# dm648_cslr_spi register map
Vendor: Texas Instruments
Peripheral module from a debugger description file.
Registers are 32-bit, access not given, reset 0x0 unless marked. A register's access mark holds for its fields unless they carry their own. Offsets are as the file gives them; lines under a group give offsets from that group; [hi:lo] are bit positions; {n}, {i} and the like mark numbered series; 'fields as' and 'values as' point back to an identical list; <NAME> marks a mode.

## SPI — Serial Peripheral Interface
0x00 SPIGCR0 — SPI Global Control Register 0
  [0] RESET rw — This bit needs to be set before any operation on SPI can be done 0: SPI is in reset state 1: SPI is out of reset state
    0=IN_RESET; 1=OUT_OF_RESET
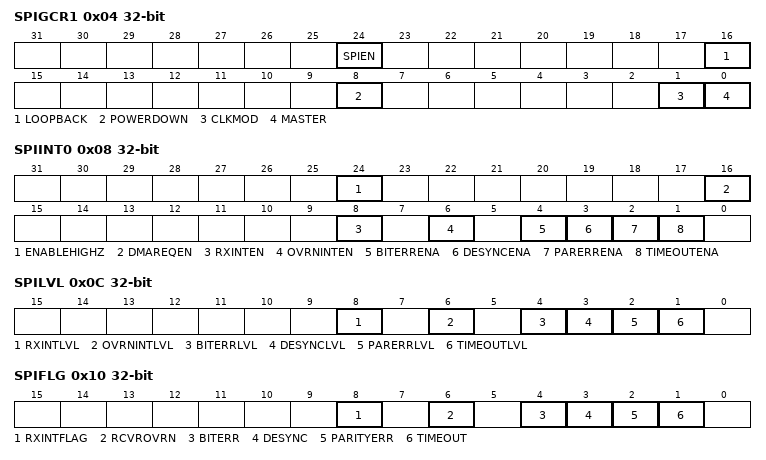
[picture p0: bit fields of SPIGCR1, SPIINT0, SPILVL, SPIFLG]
0x04 SPIGCR1 — SPI Global Control Register 1
  [24] SPIEN rw — SPI enable Holds the SPI in a reset state after a chip reset. The SPI is enabled only after a 1 is written to this bit. This bit must be setto 1 after all other SPI configuration bits have been written. This prevents an invalid operation of the SPI while the clock polarity is being changed. When this bit is 0, the SPI shift registers (SPIDAT0 and SPIDAT1) is held in reset mode and forced to 0x0000 The RXINTFLAG (SPIFLG.8) and RCVROVRN (SPIFLG.6) bits are also held in reset mode and forced to 0 when this bit is 0. SPICLK is disabled when this bit is 0 0: SPI is in reset 1: Activates SPI
    0=DISABLED; 1=ENABLED
  [16] LOOPBACK rw — Internal loop-back test mode The internal self-test option can be enabled by setting this bit. If the SPISIMO and SPISOMI pins are configured with SPI functionality, then the SPISIMOpin is internally connected to the SPISOMI pin. The transmit data is looped back as receive data and is stored in the receive field of the concerned buffer.Externally, during loop-back operation, the SPICLK pin outputs an inactive value and SPISOMI remains in high-impedance state. The SPI has to be initialized in master mode before the loop-back can be selected. If the SPI is initialized in slave mode or a data transfer is ongoing, errors may result
    0=DISABLE; 1=ENABLE
  [8] POWERDOWN rw — When active, the SPI state machines enter a powerdown state 0: SPI in active mode 1: SPI in powerdown mode
    0=ACTIVE; 1=POWERDOWN
  [1] CLKMOD rw — Selects either an internal or external clock source. This bit also determines the I/O direction of the SPIENA and SPISCS[3:0] pins in functional mode 0: Clock is external 1: Clock is internal
    0=EXTERNAL; 1=INTERNAL
  [0] MASTER rw — SPISIMO/SPISOMI pin direction determination Determines the direction of the SPISIMO and SPISOMI pins 0: SPISIMO pin an input, SPISOMI pin an output 1: SPISOMI pin an input, SPISIMO pin an output
    0=SPISIMO_OUTPUT_SPISOMI_OUTPUT; 1=SPISOMI_INPUT_SPISIMO_OUTPUT
0x08 SPIINT0 — SPI Interrupt Register
  [24] ENABLEHIGHZ rw — SPIENA pin high-z enable When active, the pin (when it is configured as a WAIT functional output signal in a slave SPI) is forced to place it's output in high-z when not driving a low signal. If inactive, then the pin will output both a high and a low signal 0: SPIENA pin is a value 1: SPIENA pin is in high-z
    0=SPIENA_VALUE; 1=SPIENA_HIZ
  [16] DMAREQEN rw — DMA request enable Enables the DMA request signal to be generated for both receive and transmit channels 0: DMA is not used 1: DMA is used
    0=DISABLED; 1=ENABLED
  [8] RXINTEN rw — An interrupt is to be generated when the RXINTFLAG bit (SPICTRL3.0) is set by hardware. Otherwise, no interrupt will be generated 0: Interrupt will not be generated 1: Interrupt will be generated
    0=DISABLED; 1=ENABLED
  [6] OVRNINTEN rw — Overrun interrupt enable An interrupt is to be generated when the RCVR OVRN flag bit (SPIFLG.6) is set by hardware. Otherwise, no interrupt will be generated 0: Overrun interrupt will not be generated 1: Overrun interrupt will be generated
    0=DISABLED; 1=ENABLED
  [4] BITERRENA rw — Enables interrupt on bit error 0: No interrupt asserted upon bit error 1: Enables an interrupt on a bit error (BITERR = 1)
    0=DISABLED; 1=ENABLED
  [3] DESYNCENA rw — Enables interrupt on de-synchronized slave DESYNCENA is used in master mode only 0: No interrupt asserted upon de-synchronization error 1: Enables an interrupt on de-synchronization of the slave (DESYNC = 1)
    0=DISABLED; 1=ENABLED
  [2] PARERRENA rw — Enables interrupt on parity error 0: No interrupt asserted upon parity error 1: Enables an interrupt on a parity error (PARITYERR = 1)
    0=DISABLED; 1=ENABLED
  [1] TIMEOUTENA rw — Enables interrupt on ENA signal time-out 0: No interrupt asserted upon ENA signal time-out 1: Enables an interrupt on a time-out of the ENA signal (TIMEOUT = 1)
    0=DISABLED; 1=ENABLED
0x0C SPILVL — SPI Level Register
  [8] RXINTLVL rw — Receive interrupt level 0: Receive interrupt is mapped to interrupt line INT0 1: Receive interrupt is mapped to interrupt line INT1
    0=RCV_INT0; 1=RCV_INT1
  [6] OVRNINTLVL rw — Receive Overrun interrupt level 0: Receive Overrun interrupt is mapped to interrupt line INT0 1: Receive Overrun interrupt is mapped to interrupt line INT1
    0=RCV_INT0; 1=RCV_INT1
  [4] BITERRLVL rw — Bit error interrupt level 0: Bit error interrupt is mapped to interrupt line INT0 1: Bit error interrupt is mapped to interrupt line INT1
    0=INT0; 1=INT1
  [3] DESYNCLVL rw — De-synchronized slave interrupt level DESYNCLVL is used in master mode only 0: An interrupt due to de-synchronization of the slave (DESYNC = 1) is mapped to interrupt line INT0 1: An interrupt due to de-synchronization of the slave (DESYNC = 1) is mapped to interrupt line INT1
    0=INT0; 1=INT1
  [2] PARERRLVL rw — Parity error interrupt level 0: A parity error interrupt (PARITYERR = 1) is mapped to interrupt line INT0 1: A parity error interrupt (PARITYERR = 1) is mapped to interrupt line INT1
    0=INT0; 1=INT1
  [1] TIMEOUTLVL rw — ENA signal time-out interrupt level 0: An interrupt on a time-out of the ENA signal (TIMEOUT = 1) is mapped to interrupt line INT0 1: An interrupt on a time-out of the ENA signal (TIMEOUT = 1) is mapped to interrupt line INT1
    0=INT0; 1=INT1
0x10 SPIFLG — SPI Flag Register
  [8] RXINTFLAG — Serves as the interrupt flag This flag is set when a word is received and copied into the buffer register (SPIBUF). If RXINTEN is enabled, an interrupt is also generated. During emulation mode, however, a read to the emulation register (SPIEMU) does not clear this flag bit. This bit is cleared in one of four ways a) Reading the SPIBUF register b)Writing a 1 to this bit c) Writing a 0 to SPIEN (SPIGCR1.24) d) System reset 0: Interrupt condition did not occur 1: Interrupt condition did occur (access RC)
    0=ENABLED; 1=DISABLED
  [6] RCVROVRN — Receiver overrun flag This bit is a read/clear only flag. The SPI hardware sets this bit when an operation completes before the previous character has been read from the buffer. The bit indicates that the last received character has been overwritten and therefore lost. The SPI will generate an interrupt request if this bit is set and the OVRN INTEN bit (SPIINT0.6) is set high This bit is cleared in one of four ways: a) Reading the SPIBUF register b) Writing a 1 to this bit c) Writing a 0 to SPIEN (SPIGCR1.24) d) System reset 0: Overrun condition did not occur 1: Overrun condition has occurred (access RC)
    0=ENABLED; 1=DISABLED
  [4] BITERR — Mismatch of internal transmit data and transmitted data This flag is read/clear only flag, i.e. reading the flag will automatically clear it 0: No bit error occurred 1: A bit error occurred. The SPI samples the signal of the transmit pin (master: SIMO, slave: SOMI) at the receive point (half clock cycle after transmit point). If the sampled value differs from the transmitted value a bit error is detected and the Flag BITERR is set. If BIT-ERRENA is set an interrupt is asserted. A possible reason for a bit error can be a to high bit rate / capacitive load or another master/slave trying to transmit at the same time (access RC)
    0=NO_ERROR; 1=ERROR
  [3] DESYNC — De-synchronization of slave device This flag is read/clear only flag, i.e. reading the flag will automatically clear it De-synchronization monitor is active in master mode only 0: No slave de-synchronization detected 1: A slave device is de-synchronized. The master monitors the ENABLE signal coming from the slave device and sets the DESYNC flag if ENA is deactivated before the last reception point or after the last bit is transmitted plus tT2EDELAY. If DESYNCENA is set an interrupt is asserted. De-synchronization can occur if a slave device misses a clock edge coming from the master or is detecting an additional clock edge due to perturbation (access RC)
    0=ENABLED; 1=DISABLED
  [2] PARITYERR — Calculated parity differs from received parity bit This flag is read/clear only flag, i.e. reading the flag will automatically clear it 0: No parity error detected 1: A parity error occurred. If the parity generator is enabled (can be selected individually for each buffer) an even or odd parity bit is added at the end of a data word. During reception of the data word the parity generator calculates the reference parity and compares it to the received parity bit. In the event of a mismatch the PARITYERR flag is set and an interrupt is asserted if PARERRENA is set (access RC)
    0=NO_ERROR; 1=ERROR
  [1] TIMEOUT — Time-out due to non-activation of ENA signal This flag is read/clear only flag, i.e. reading the flag will automatically clear it 0: No ENA-signal time-out occurred 1: An ENA signal time-out occurred. The SPI generates a time-out because the slave hasn't responded in time by activating the ENA signal after the chip select signal has been activated. If a time-out condition is detected the corresponding chip select is deactivated immediately and the TIMEOUT flag is set. In addition the TIMOUT flag in the status field of the corresponding buffer is set. The transmit request of the concerned buffer is cleared, i.e. the SPIdoesn't restart a data transfer from this buffer (access RC)
    0=DISABLED; 1=ENABLED
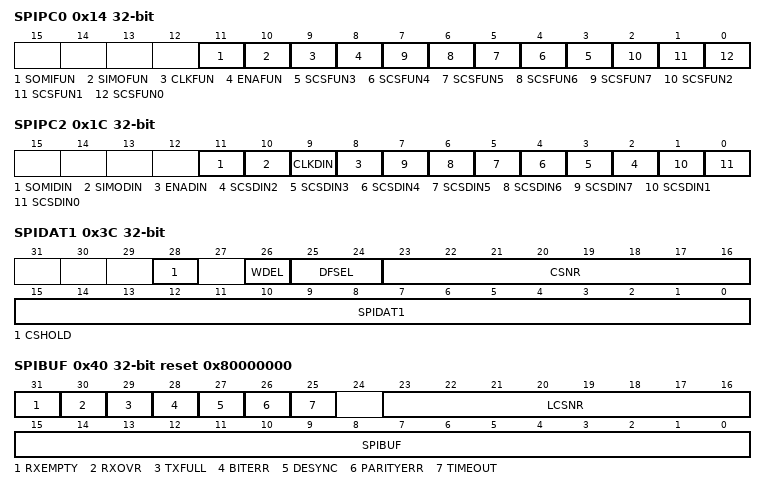
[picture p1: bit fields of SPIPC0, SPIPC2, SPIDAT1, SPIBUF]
0x14 SPIPC0 — SPI Pin Control Register 0
  [all] fields
    0=GPIO; 0=SPI
  [11] SOMIFUN rw — Slave out, master in function Determines whether the SPISOMI pin is to be used as a general-purpose I/O pin or as a SPI functional pin. 0: SPISOMI pin is a GPIO 1: SPISOMI pin is a SPI functional pin
  [10] SIMOFUN rw — Slave in, master out function Determines whether the SPISIMO pin is to be used as a general-purpose I/O pin, or as a SPI functional pin. 0: SPISIMO pin is a GPIO 1: SPISIMO pin is a SPI functional pin
  [9] CLKFUN rw — SPI clock function Determines whether the SPICLK pin is to be used as a general-purpose I/O pin, or as a SPI functional pin. 0: SPICLK pin is a GPIO 1: SPICLK pin is a SPI functional pin
  [8] ENAFUN rw — SPIENA function Determines whether the SPIENA pin is to be used as a general-purpose I/O pin, or as a SPI functional pin 0: SPIENA pin is a GPIO 1: SPIENA pin is a SPI functional pin
  [n] SCSFUN{n} rw (n=3..7) — SPISCS{n} function Determines whether the SPISCS{n} pin are to be used as a general-purpose I/O pin or as SPI functional pin. If the slave SPISCS{n} pin are in functional mode and receive an inactive high signal, the slave SPI will place it's output in high-z and disable shifting 0: SPISCS{n} pin is a GPIO 1: SPISCS{n} pin is a SPI functional pin
  [2] SCSFUN2 rw — SPISCS7 function Determines whether the SPISCS2 pin are to be used as a general-purpose I/O pin or as SPI functional pin. If the slave SPISCS2 pin are in functional mode and receive an inactive high signal, the slave SPI will place it's output in high-z and disable shifting 0: SPISCS2 pin is a GPIO 1: SPISCS2 pin is a SPI functional pin
  [1] SCSFUN1 rw — SPISCS1 function Determines whether the SPISCS1 pin are to be used as a general-purpose I/O pin or as SPI functional pin. If the slave SPISCS1 pin are in functional mode and receive an inactive high signal, the slave SPI will place it's output in high-z and disable shifting 0: SPISCS1 pin is a GPIO 1: SPISCS1 pin is a SPI functional pin
  [0] SCSFUN0 rw — SPISCS0 function Determines whether the SPISCS0 pin are to be used as a general-purpose I/O pin or as SPI functional pin. If the slave SPISCS0 pin are in functional mode and receive an inactive high signal, the slave SPI will place it's output in high-z and disable shifting 0: SPISCS0 pin is a GPIO 1: SPISCS0 pin is a SPI functional pin
0x1C SPIPC2 — SPI Pin Control Register 2
  [all] fields
    0=LOW; 1=HIGH
  [11] SOMIDIN ro — SPISOMI data in Reflects the value of the SPISOMI pin 0: Current value on SPISOMI pin is logic 0 1: Current value on SPISOMI pin is logic 1
  [10] SIMODIN ro — SPISIMO data in Reflects the value of the SPISIMO pin 0: Current value on SPISIMO pin is logic 0 1: Current value on SPISIMO pin is logic 1
  [9] CLKDIN ro — Clock data in Reflects the value of the SPICLK pin 0: Current value on SPICLK pin is logic 0 1: Current value on SPICLK pin is logic 1
  [8] ENADIN ro — SPIENA data in Reflects the value of the SPIENA pin 0: Current value on SPIENA pin is logic 0 1: Current value on SPIENA pin is logic 1
  [n] SCSDIN{n} ro (n=2..7) — SPISCS{n} data in Reflects the value of the SPISCS{n} pins 0: Current value on SPISCS{n} pin is logic 0 1: Current value on SPISCS{n} pin is logic 1
  [1] SCSDIN1 ro — SPISCS1data in Reflects the value of the SPISCS1 pins. 0: Current value on SPISCS1 pin is logic 0 1: Current value on SPISCS2 pin is logic 1
  [0] SCSDIN0 ro — SPISCS0data in Reflects the value of the SPISCS0 pins 0: Current value on SPISCS0 pin is logic 0 1: Current value on SPISCS0 pin is logic 1
0x3C SPIDAT1 — SPI Shift Register 1
  [28] CSHOLD rw — Chip select hold mode CSHOLD is considered in master mode only. In slave mode this bit has no meaning. CSHOLD defines the behavior of the chip select line at the end of a data transfer 0: The chip select signal is deactivated at the end of a transfer after the T2CDELAY time has passed. If two consecutive transfers are dedicated to the same chip select this chip select signal will be shortly deactivated before it is activated again 1: The chip select signal is held active at the end of a transfer until a control field with new data and control information is loaded into SPIDAT1. If the new chip select information equals the previous one the active chip select signal is extended until the end of transfer with CSHOLD cleared or until the chip select information changes
    0=DISABLED; 1=ENABLED
  [26] WDEL rw — Enable the delay counter at the end of the current transaction 0: No delay is inserted 1: After the transaction WDELAY of the corresponding data format is loaded into the delay counter. No transaction is performed until the counter is reset
    0=NODELAY; 1=DEYAL
  [25:24] DFSEL rw — Data word format select -------------------------------------------------------------------------------- DFSEL1 DFSEL0 Description --------------------------------------------------------------------------------- 0 0 Data word format 0 is selected 0 1 Data word format 1 is selected 1 0 Data word format 2 is selected 1 1 Data word format 3 is selected
  [23:16] CSNR rw — Chip select number CSNR defines the chip select that shall be activated during the data transfer
  [15:0] SPIDAT1 rw — SPI shift data 1 These bits make up the SPI shift register 1. Data is shifted out of the MSB (bit 15) and into the LSB (bit 0) SPIEN must be set to 1 before this register can be written to. Writing a 0 to the SPIEN register forces the lower 16 bits of the SPIDAT1 register to 0x00 Write to this register ONLY when using the automatic Slave Chip Select feature. A write to this register will drive the SPISCS signal low When data is read from this register, the value is indeterminate because of the shift operation. The value in the buffer register (SPIBUF) should be read after the shift operation is complete to determine what data was shifted into the SPIDAT1 register
0x40 SPIBUF reset 0x80000000 — SPI Buffer Register
  [31] RXEMPTY ro — Receive data buffer empty This flag is a read-only flag. When host reads the SPIBUF field or the whole SPIBUF register this will automatically set the RXEMPTY flag. When a data transfer has been finished and the received data is copied into SPIBUF the RXEMPTY flag is cleared 0: Data is received and copied into SPIBUF field 1: No data received since last reading of SPIBUF register
    0=YES; 1=NO
  [30] RXOVR — Receive data buffer overrun This flag is read/clear only flag, i.e. reading the flag will automatically clear it. When a data transfer has been finished and the received data is copied into the SPIBUF while RXEMPTY flag is already cleared RXOVR is set 0: No receive data overrun condition occurred since last time reading the status field 1: A receive data overrun condition occurred since last time reading the status field (access RC)
    0=NO; 1=YES
  [29] TXFULL ro — Transmit data buffer full This flag is a read-only flag. Writing into SPIDAT0 or SPIDAT1 field will automatically set the TXFULL flag. After transfer of the transmit data the TXFULL flag is cleared 0: No new transmit data from host since previous transfer of transmit data 1: Host provided new transmit data to SPIDAT0 or SPIDAT1
    0=NO; 1=YES
  [28] BITERR — Mismatch of internal transmit data and transmitted data This flag is read/clear only flag, i.e. reading the flag will automatically clear it. It represents a copy of the BITERR flag in SPIFLG 0: No bit error occurred 1: A bit error occurred. The SPI samples the signal of the transmit pin (master: SIMO, slave: SOMI) at the receive point (half clock cycle after transmit point). If the sampled value differs from the transmitted value a bit error is detected and the flag BITERR is set. A possible reason for a bit error can be noise, a to high bit rate / capacitive load or another master/slave trying to transmit at the same time (access RC)
    0=NO; 1=YES
  [27] DESYNC — De-synchronization of slave device This flag is read/clear only flag, i.e. reading the flag will automatically clear it. De-synchronization monitor is active in master mode only. DESYNC represents a copy of the DESYNC flag in SPIFLG 0: No slave de-synchronization detected 1: A slave device is de-synchronized. The master monitors the ENA signal coming from the slave device and sets the DESYNC flag if ENA is deactivated before the last reception point or after the last bit is transmitted plus t T2EDELAY. If DESYNCENA is set an interrupt is asserted. De-synchronization can occur if a slave device misses a clock edge coming from the master or is detecting an additional clock edge due to perturbation (access RC)
    0=NO; 1=YES
  [26] PARITYERR — Calculated parity differs from received parity bit This flag is read/clear only flag, i.e. reading the flag will automatically clear it. It represents a copy of the PARITYERR flag in SPIFLG 0: No parity error detected 1: A parity error occurred. If the parity generator is enabled (can be selected individually for each buffer) an even or odd parity bit is added at the end of a data word. During reception of the data word the parity generator calculates the reference parity and compares it to the received parity bit. In the event of a mismatch the PARITYERR flag is set (access RC)
    0=NO; 1=YES
  [25] TIMEOUT — Time-out due to non-activation of ENA signal This flag is read/clear only flag, i.e. reading the flag will automatically clear it 0: No ENA-signal time-out occurred 1: An ENA signal time-out occurred. The SPI generates a time-out because the slave hasn't responded in time by activating the ENA signal after the chip select signal has been activated. If a time-out condition is detected the corresponding chip select is deactivated immediately and the TIMEOUT flag is set. In addition the TIMOUT flag in the status field of the corresponding buffer and in the SPISTAT register is set (access RC)
    0=NO; 1=YES
  [23:16] LCSNR ro — LCSNR in the status field is a copy of CSNR in the corresponding control field It defines the chip select that has been activated during the last data transfer from the corresponding buffer. LCSNR is copied from the Kernel of SPI after transmission during write back of received data
  [15:0] SPIBUF ro — SPI Buffer The data in this register is the data transferred from the shift-register (SPIDAT). Since the data is shifted into the SPI most significant bit first, for word lengths less than 16, the data is stored right-justified in the register
0x44 SPIEMU — SPI Emulation Register
  [15:0] SPIEMU ro — SPI Emulation SPI emulation is a mirror of the SPIBUF register. The only difference between SPIEMU and SPIBUF is that a read from SPIEMU does not clear the RCVR OVRN (SPIFLG.6) or RXINTFLAG (SPIFLG.8) bits
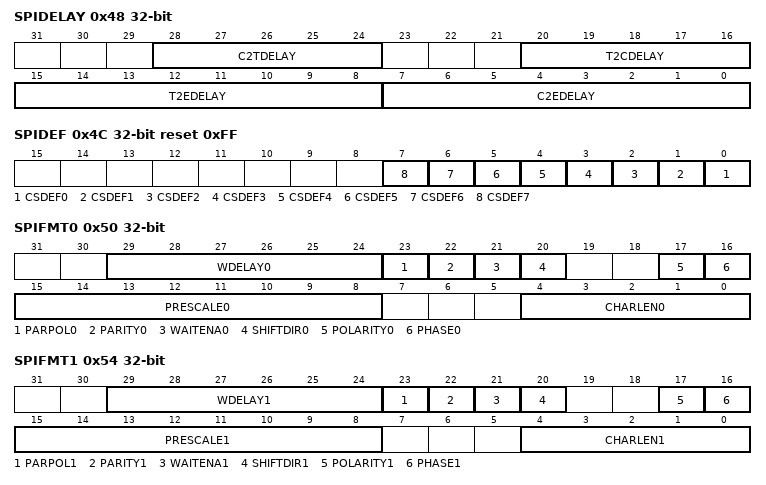
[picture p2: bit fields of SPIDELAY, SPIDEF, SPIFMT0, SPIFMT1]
0x48 SPIDELAY
  [28:24] C2TDELAY rw — Chip select active to transmit start delay C2TDELAY is used in master mode only. If the slave device indicates the ready-to-transfer status via the ENA signal, C2TDELAY time is not delayed after the ENA signal is activated. It defines a setup time for the slave device that delays the data transmission from the chip select active edge by a multiple of VBUSPCLK cycles. C2TDELAY can be configured between 2 and 33 VBUSPCLK cycles
  [20:16] T2CDELAY rw — Transmit end to chip select inactive delay T2CDELAY is used in master mode only. It defines a hold time for the slave device that delays the chip select deactivation by a multiple of VBUSPCLK cycles after the last bit is transferred. T2CDELAY can be configured between 1 and 32 VBUSPCLK cycles
  [15:8] T2EDELAY rw — Transmit data finished to ENA pin inactive timeout T2EDELAY is used in master mode only. It defines a time-out value as a multiple of SPI clock before the ENAble signal has to become inactive and after the CS becomes inactive. The SPI clock depends on which data format is selected. If the slave device is missing one or more clock edges, it's becoming de-synchronized. Although the master has finished the data transfer the slave is still waiting for the missed clock pulses and the ENA signal isn't disabled. The T2EDELAY defines a time-out value that triggers the DESYNC flag, if the ENA signal isn't deactivated in time
  [7:0] C2EDELAY rw — Chip select active to ENA signal active timeout C2EDELAY is utilized only in master mode and it applies only if the addressed slave generates an ENA signal as a hardware handshake response. C2EDELAY defines the maximum time between the SPI activates the chip select signal and the addressed slave has to respond by activating the ENA signal. C2EDELAY defines a time-out value as a multiple of SPI clocks. The SPI clock depends on whether data format 0 or data format 1 is selected. If the slave device is not responding with the ENA signal before the time-out value is reached, the TIMEOUT flag in SPISTAT register is set and a interrupt is asserted if enabled
0x4C SPIDEF reset 0xFF — SPI Chipselect Default Regsiter
  [all] fields
    0=CS_0; 1=CS_1
  [n] CSDEF{n} rw (n=0..7) — Chip select default pattern Master mode behavior. The CSDEF{n} register is output to the chip select pin when no transmission are currently performed. It allows the user to set a chip select pattern which deselect all the SPI slaves 0: If CSDEF{n} is set to "0" the corresponding chip select is set to "0" when no transfer occurs 1: If CSDEF{n} is set to "1" the corresponding chip select is set to "1" when no transfer occurs
0x50 SPIFMT0 — SPI Format 0 Register
  [29:24] WDELAY0 rw — Delay in between transmissions for data format 0 Idle time that will be applied at the end of the current transmission if the bit WDEL is set in the current buffer The delay to be applied is equal to: WDELAY * PVBUSPCLK + 2 * PVBUSPCLK
  [23] PARPOL0 rw — Parity polarity: even or odd. PARPOL0 can be modified in privilege mode only 0: If PARPOL0 is set to "0" and PARITY0 is enabled, a even parity flag is added at the end of the transmit data stream 1: If PARPOL0 is set to "1" and PARITY0 is enabled, a odd parity flag is added at the end of the transmit data stream
    0=EVEN; 1=ODD
  [22] PARITY0 rw — Parity enable for data format 0 0: No parity generation/ verification is performed for this data format 1: A parity is added after transfer of the data bit. At the end of a transfer the parity generator compares the received parity bit with the locally calculated parity flag. If the parity bits do not match the RXERR flag is set in the corresponding control field. The parity type (even or odd) can be selected via the PARPOL bit
    0=NOPARITY; 1=PARITY
  [21] WAITENA0 rw — Master waits for ENA signal from slave for data format 0. WAITENA is considered in master mode only. In slave mode this bit has no meaning. WAITENA enables a flexible SPI network where slaves with ENA signal and slaves without ENA signal can be mixed. WAITENA defines for each buffer whether the addressed slave generates the ENA signal or does not 0: The SPI does not wait for the ENA signal from the slaves and directly starts the transfer 1: Before the SPI starts the data transfer it waits for the ENA signal to become low. If the ENA signal is not pulled down by the addressed slave before the internal time-out counter (CE2DELAY) expires
    0=NO_WAIT; 1=WAIT
  [20] SHIFTDIR0 rw — Shift direction for data format 0 With bit SHIFTDIR0 the shift direction for data format 0 can be selected 0: Data format 0 shift direction: Most significant bit is shifted out first 1: Data format 0 shift direction: Least significant bit is shifted out first
    0=MSB; 1=LSB
  [17] POLARITY0 rw — SPI data format 0 clock polarity POLARITY0 defines the clock polarity of data format 0. POLARITY0 can be modified in privilege mode only 0: If POLARITY0 is set to "0" the SPI clock signal is low-inactive, i.e. before and after data transfer the clock signal is low 1: If POLARITY0 is set to "1" the SPI clock signal is high-inactive, i.e. before and after data transfer the clock signal is high
    0=LOW; 1=HIGH
  [16] PHASE0 rw — SPI Data format 0 clock delay PHASE0 defines the clock delay of data format 0. PHASE0 can be modified in privilege mode only 0: If PHASE0 is set to "0" the SPI clock signal is not delayed versus the transmit / receive data stream. The first data bit is transmitted with the first clock edge and the first bit is received with the second (inverse) clock edge 1: If PHASE0 is set to "1" the SPI clock signal is delayed by a half SPI clock cycle versus the transmit / receive data stream. The first transmit bit has to output prior to the first clock edge. Master and slave receive the first bit with the first edge
    0=NO_DELAY; 1=DELAY
  [15:8] PRESCALE0 rw — SPI data format 0 prescaler PRESCALE0 can be modified in privilege mode only PRESCALE0 determines the bit transfer rate of data format 0 if the SPI is the network master. PRESCALE0 is directly derived from VBUSPCLK. If the SPI is configured as slave, PRESCALE0 DOES NOT NEED to be configured. When PRESCALE0 is set to zero (0), the SPI clock rate is VBUSPCLK/2
  [4:0] CHARLEN0 rw — SPI data format 0 data word length CHARLEN0 defines the word length of data format 0. Legal values are 0x02 (data word length = 2 bit) to 0x10 (data word length = 16). Illegal values, such as 0x00 or 0x1F are not detected and their effect is indeterminate
0x54 SPIFMT1 — SPI Format 1 Register
  [29:24] WDELAY1 rw — Delay in between transmissions for data format 1 Idle time that will be applied at the end of the current transmission if the bit WDEL is set in the current buffer The delay to be applied is equal to: WDELAY * PVBUSPCLK + 2 * PVBUSPCLK
  [23] PARPOL1 rw — Parity polarity: even or odd. PARPOL1 can be modified in privilege mode only 0: If PARPOL1 is set to "0" and PARITY1 is enabled, a even parity flag is added at the end of the transmit data stream 1: If PARPOL1 is set to "1" and PARITY1 is enabled, a odd parity flag is added at the end of the transmit data stream
    0=EVEN; 1=ODD
  [22] PARITY1 rw — Parity enable for data format 1 0: No parity generation/ verification is performed for this data format 1: A parity is added after transfer of the data bit. At the end of a transfer the parity generator compares the received parity bit with the locally calculated parity flag. If the parity bits do not match the RXERR flag is set in the corresponding control field. The parity type (even or odd) can be selected via the PARPOL bit
    0=NOPARITY; 1=PARITY
  [21] WAITENA1 rw — Master waits for ENA signal from slave for data format1 WAITENA is considered in master mode only. In slave mode this bit has no meaning. WAITENA enables a flexible SPI network where slaves with ENA signal and slaves without ENA signal can be mixed. WAITENA defines for each buffer whether the addressed slave generates the ENA signal or does not 0: The SPI does not wait for the ENA signal from the slaves and directly starts the transfer 1: Before the SPI starts the data transfer it waits for the ENA signal to become low. If the ENA signal is not pulled down by the addressed slave before the internal time-out counter (CE2DELAY) expires
    0=NO_WAIT; 1=WAIT
  [20] SHIFTDIR1 rw — Shift direction for data format 1 With bit SHIFTDIR1 the shift direction for data format 1 can be selected 0: Data format 1shift direction: Most significant bit is shifted out first 1: Data format 1shift direction: Least significant bit is shifted out first
    0=MSB; 1=LSB
  [17] POLARITY1 rw — SPI data format 1 clock polarity POLARITY1 defines the clock polarity of data format 1. POLARITY1 can be modified in privilege mode only 0: If POLARITY1 is set to "0" the SPI clock signal is low-inactive, i.e. before and after data transfer the clock signal is low 1: If POLARITY1 is set to "1" the SPI clock signal is high-inactive, i.e. before and after data transfer the clock signal is high
    0=LOW; 1=HIGH
  [16] PHASE1 rw — SPI Data format 1 clock delay PHASE1 defines the clock delay of data format 1. PHASE1 can be modified in privilege mode only 0: If PHASE1 is set to "0" the SPI clock signal is not delayed versus the transmit / receive data stream. The first data bit is transmitted with the first clock edge and the first bit is received with the second (inverse) clock edge 1: If PHASE1 is set to "1" the SPI clock signal is delayed by a half SPI clock cycle versus the transmit / receive data stream. The first transmit bit has to output prior to the first clock edge. Master and slave receive the first bit with the first edge
    0=NO_DELAY; 1=DELAY
  [15:8] PRESCALE1 rw — SPI data format 1 prescaler PRESCALE1 can be modified in privilege mode only PRESCALE1 determines the bit transfer rate of data format 1 if the SPI is the network master. PRESCALE1 is directly derived from VBUSPCLK. If the SPI is configured as slave, PRESCALE1 DOES NOT NEED to be configured. When PRESCALE1 is set to zero (0), the SPI clock rate is VBUSPCLK/2
  [4:0] CHARLEN1 rw — SPI data format 1 data word length CHARLEN1 defines the word length of data format 1. Legal values are 0x02 (data word length = 2 bit) to 0x10 (data word length = 16). Illegal values, such as 0x00 or 0x1F are not detected and their effect is indeterminate
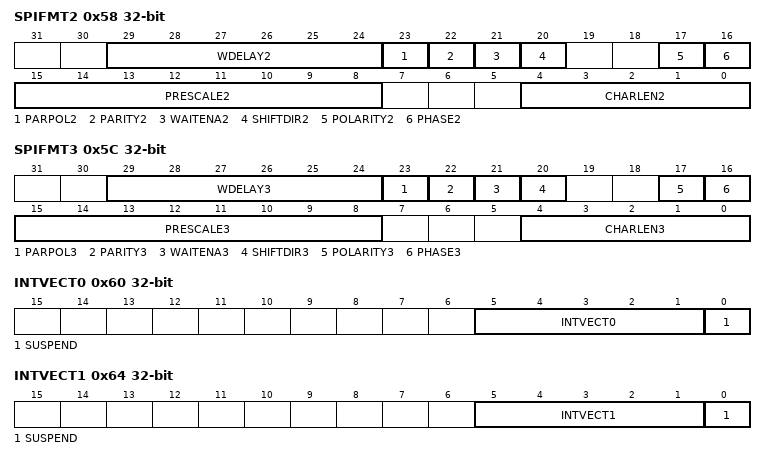
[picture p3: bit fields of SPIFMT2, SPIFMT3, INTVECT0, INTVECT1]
0x58 SPIFMT2 — SPI Format 2 Register
  [29:24] WDELAY2 rw — Delay in between transmissions for data format 2 Idle time that will be applied at the end of the current transmission if the bit WDEL is set in the current buffer The delay to be applied is equal to: WDELAY * PVBUSPCLK + 2 * PVBUSPCLK
  [23] PARPOL2 rw — Parity polarity: even or odd. PARPOL2 can be modified in privilege mode only 0: If PARPOL2 is set to "0" and PARITY2 is enabled, a even parity flag is added at the end of the transmit data stream 1: If PARPOL2 is set to "1" and PARITY2 is enabled, a odd parity flag is added at the end of the transmit data stream
    0=EVEN; 1=ODD
  [22] PARITY2 rw — Parity enable for data format 2 0: No parity generation/ verification is performed for this data format 1: A parity is added after transfer of the data bit. At the end of a transfer the parity generator compares the received parity bit with the locally calculated parity flag. If the parity bits do not match the RXERR flag is set in the corresponding control field. The parity type (even or odd) can be selected via the PARPOL bit
    0=NOPARITY; 1=PARITY
  [21] WAITENA2 rw — Master waits for ENA signal from slave for data format 2 WAITENA is considered in master mode only. In slave mode this bit has no meaning. WAITENA enables a flexible SPI network where slaves with ENA signal and slaves without ENA signal can be mixed. WAITENA defines for each buffer whether the addressed slave generates the ENA signal or does not 0: The SPI does not wait for the ENA signal from the slaves and directly starts the transfer 1: Before the SPI starts the data transfer it waits for the ENA signal to become low. If the ENA signal is not pulled down by the addressed slave before the internal time-out counter (CE2DELAY) expires
    0=NO_WAIT; 1=WAIT
  [20] SHIFTDIR2 rw — Shift direction for data format 2 With bit SHIFTDIR2 the shift direction for data format 2 can be selected 0: Data format 2 shift direction: Most significant bit is shifted out first 1: Data format 2 shift direction: Least significant bit is shifted out first
    0=MSB; 1=LSB
  [17] POLARITY2 rw — SPI data format 2 clock polarity POLARITY2 defines the clock polarity of data format 2. POLARITY2 can be modified in privilege mode only 0: If POLARITY2 is set to "0" the SPI clock signal is low-inactive, i.e. before and after data transfer the clock signal is low 1: If POLARITY2 is set to "1" the SPI clock signal is high-inactive, i.e. before and after data transfer the clock signal is high
    0=LOW; 1=HIGH
  [16] PHASE2 rw — SPI Data format 2 clock delay PHASE2 defines the clock delay of data format 2. PHASE2 can be modified in privilege mode only 0: If PHASE2 is set to "0" the SPI clock signal is not delayed versus the transmit / receive data stream. The first data bit is transmitted with the first clock edge and the first bit is received with the second (inverse) clock edge 1: If PHASE2 is set to "1" the SPI clock signal is delayed by a half SPI clock cycle versus the transmit / receive data stream. The first transmit bit has to output prior to the first clock edge. Master and slave receive the first bit with the first edge
    0=NO_DELAY; 1=DELAY
  [15:8] PRESCALE2 rw — SPI data format 2 prescaler PRESCALE2 can be modified in privilege mode only PRESCALE2 determines the bit transfer rate of data format 2 if the SPI is the network master. PRESCALE2 is directly derived from VBUSPCLK. If the SPI is configured as slave, PRESCALE2 DOES NOT NEED to be configured. When PRESCALE2 is set to zero (0), the SPI clock rate is VBUSPCLK/2
  [4:0] CHARLEN2 rw — SPI data format 2 data word length CHARLEN2 defines the word length of data format 1. Legal values are 0x02 (data word length = 2 bit) to 0x10 (data word length = 16). Illegal values, such as 0x00 or 0x1F are not detected and their effect is indeterminate
0x5C SPIFMT3 — SPI Format 3 Register
  [29:24] WDELAY3 rw — Delay in between transmissions for data format 3 Idle time that will be applied at the end of the current transmission if the bit WDEL is set in the current buffer The delay to be applied is equal to: WDELAY * PVBUSPCLK + 2 * PVBUSPCLK
  [23] PARPOL3 rw — Parity polarity: even or odd. PARPOL3 can be modified in privilege mode only 0: If PARPOL3 is set to "0" and PARITY3 is enabled, a even parity flag is added at the end of the transmit data stream 1: If PARPOL3 is set to "1" and PARITY3 is enabled, a odd parity flag is added at the end of the transmit data stream
    0=EVEN; 1=ODD
  [22] PARITY3 rw — Parity enable for data format 3 0: No parity generation/ verification is performed for this data format 1: A parity is added after transfer of the data bit. At the end of a transfer the parity generator compares the received parity bit with the locally calculated parity flag. If the parity bits do not match the RXERR flag is set in the corresponding control field. The parity type (even or odd) can be selected via the PARPOL bit
    0=NOPARITY; 1=PARITY
  [21] WAITENA3 rw — Master waits for ENA signal from slave for data format 3 WAITENA is considered in master mode only. In slave mode this bit has no meaning. WAITENA enables a flexible SPI network where slaves with ENA signal and slaves without ENA signal can be mixed. WAITENA defines for each buffer whether the addressed slave generates the ENA signal or does not 0: The SPI does not wait for the ENA signal from the slaves and directly starts the transfer 1: Before the SPI starts the data transfer it waits for the ENA signal to become low. If the ENA signal is not pulled down by the addressed slave before the internal time-out counter (CE2DELAY) expires
    0=NO_WAIT; 1=WAIT
  [20] SHIFTDIR3 rw — Shift direction for data format 3 With bit SHIFTDIR3 the shift direction for data format 3 can be selected 0: Data format 3 shift direction: Most significant bit is shifted out first 1: Data format 3 shift direction: Least significant bit is shifted out first
    0=MSB; 1=LSB
  [17] POLARITY3 rw — SPI data format 3 clock polarity POLARITY3 defines the clock polarity of data format 3. POLARITY3 can be modified in privilege mode only 0: If POLARITY3 is set to "0" the SPI clock signal is low-inactive, i.e. before and after data transfer the clock signal is low 1: If POLARITY3 is set to "1" the SPI clock signal is high-inactive, i.e. before and after data transfer the clock signal is high
    0=LOW; 1=HIGH
  [16] PHASE3 rw — SPI Data format 3 clock delay PHASE3 defines the clock delay of data format 3. PHASE3 can be modified in privilege mode only 0: If PHASE3 is set to "0" the SPI clock signal is not delayed versus the transmit / receive data stream. The first data bit is transmitted with the first clock edge and the first bit is received with the second (inverse) clock edge 1: If PHASE3 is set to "1" the SPI clock signal is delayed by a half SPI clock cycle versus the transmit / receive data stream. The first transmit bit has to output prior to the first clock edge. Master and slave receive the first bit with the first edge
    0=NO_DELAY; 1=DELAY
  [15:8] PRESCALE3 rw — SPI data format 3 prescaler PRESCALE3 can be modified in privilege mode only PRESCALE3 determines the bit transfer rate of data format 3 if the SPI is the network master. PRESCALE3 is directly derived from VBUSPCLK. If the SPI is configured as slave, PRESCALE3 DOES NOT NEED to be configured. When PRESCALE3 is set to zero (0), the SPI clock rate is VBUSPCLK/2
  [4:0] CHARLEN3 rw — SPI data format 3 data word length CHARLEN3 defines the word length of data format 3. Legal values are 0x02 (data word length = 2 bit) to 0x10 (data word length = 16). Illegal values, such as 0x00 or 0x1F are not detected and their effect is indeterminate
0x60 INTVECT0 — SPI Interrupt Vector Register 0
  [5:1] INTVECT0 ro — Interrupt vector for interrupt line INT0 INTVECT0 returns the vector of the pending interrupt at interrupt line INT0. If more than one interrupt is pending, INTVECT0 always references the highest prior interrupt source first The interrupts available for SPI, in the descending order of their priorities are as given below a) Receive Overrun Interrupt b) Receive Interrupt c) Transmission error Interrupt Vectors for each of these interrupts will be reflected on the INTVECT0 bits, when they occur. Reading the vectors for the Receive Overrun interrupt and Receive interrupt will automatically clear the respective flags in the SPIFLG register. On reading the INTVECT0 bits, the vector of the next highest priority interrupt (if any) will be then reflected on the INTVECT0 bits.If two or more interrupts occur simultaneously, the vector for the higest priority interrupt will be reflected on the INTVECT0 bits
  [0] SUSPEND ro — "Transfer suspended" or "transfer finished" interrupt Every time TGINTVECT0 is read by the host the corresponding interrupt flag of the referenced transfer group is cleared and TGINTVECT0 is updated with the vector coming next in the priority chain. In parallel the SUSPEND flag is updated depending on the type of interrupt 0: The interrupt type is a "transfer finished" interrupt. I.e. the buffer array referenced by INTVECT0 has asserted an interrupt, because all data from the whole transfer group has been transferred. The SUSPEND bit always returns value '0' in SPI 1: The interrupt type is a "transfer suspended" interrupt. I.e. the transfer group referenced by INTVECT0 has asserted an interrupt, because the buffer to be transferred next is in "suspend to wait" mode
    0=TRANSFER_FINISHED; 1=TRANSFER_SUSPENDED
0x64 INTVECT1 — SPI Interrupt Vector Register 1
  [5:1] INTVECT1 ro — Interrupt vector for interrupt line INT1 INTVECT1 returns the vector of the pending interrupt at interrupt line INT1. If more than one interrupt is pending, INTVECT1 always references the highest prior interrupt source first The interrupts available for SPI, in the descending order of their priorities are as given below a) Receive Overrun Interrupt b) Receive Interrupt c) Transmission error Interrupt Vectors for each of these interrupts will be reflected on the INTVECT1 bits, when they occur. Reading the vectors for the Receive Overrun interrupt and Receive interrupt will automatically clear the respective flags in the SPIFLG register. On reading the INTVECT1 bits, the vector of the next highest priority interrupt (if any) will be then reflected on the INTVECT1 bits.If two or more interrupts occur simultaneously, the vector for the higest priority interrupt will be reflected on the INTVECT1 bits
  [0] SUSPEND ro — "Transfer suspended" or "transfer finished" interrupt Every time TGINTVECT1 is read by the host the corresponding interrupt flag of the referenced transfer group is cleared and TGINTVECT1 is updated with the vector coming next in the priority chain. In parallel the SUSPEND flag is updated depending on the type of interrupt 0: The interrupt type is a "transfer finished" interrupt. I.e. the buffer array referenced by INTVECT1 has asserted an interrupt, because all data from the whole transfer group has been transferred. The SUSPEND bit always returns value '0' in SPI 1: The interrupt type is a "transfer suspended" interrupt. I.e. the transfer group referenced by INTVECT1 has asserted an interrupt, because the buffer to be transferred next is in "suspend to wait" mode
    0=TRANSFER_FINISHED; 1=TRANSFER_SUSPENDED
